# STM32H743 register map
File version: 2.4
CPU: CM7 r0p1, little endian, MPU, FPU, 4 interrupt priority bits
Registers are 32-bit, read-write, reset 0x0 unless marked. A register's access mark holds for its fields unless they carry their own. Offsets are from the block's base; [hi:lo] are bit positions; {n}, {i} and the like mark numbered series; 'fields as' and 'values as' point back to an identical list.

## JPEG — JPEG 编解码器
Base 0x52003000
0x00 CONFR0 wo — JPEG 编解码器控制寄存器
  [0] START — 启动 此位用于启动或停止编码/解码过程。读取此位始终返回 0。
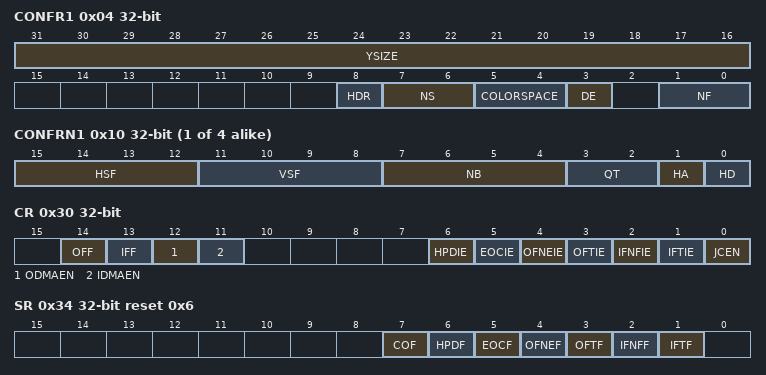
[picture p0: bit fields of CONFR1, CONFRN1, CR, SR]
0x04 CONFR1 — JPEG 编解码器配置寄存器 1
  [31:16] YSIZE — Y 方向尺寸 此字段定义源图像的行数。
  [8] HDR — 头处理 此位使能头处理（生成/解析）。
  [7:6] NS — 扫描分量数 此字段定义扫描头标记段的分量数减 1。
  [5:4] COLORSPACE — 颜色空间 此字段定义输出流中要插入的量化表数量减 1。
  [3] DE — 解码使能 此位选择编码或解码过程。
  [1:0] NF — 颜色分量数 此字段定义颜色分量数减 1。
0x08 CONFR2 — JPEG 编解码器配置寄存器 2
  [25:0] NMCU — MCU 数量 编码时：此字段定义要编码的 MCU 单元数减 1。解码时：此字段指示要解码的完整 MCU 单元数减 1（此字段在 JPEG 头解析后更新）。如果解码图像的 X 或 Y 尺寸不是 8 或 16 的倍数（取决于子采样过程），则需将由此产生的不完整或空的 MCU 计入此值，以得到生成的总 MCU 数。
0x0C CONFR3 — JPEG 编解码器配置寄存器 3
  [31:16] XSIZE — X 方向尺寸 此字段定义每行的像素数。
{0xC+4i} CONFRN{i} (i=1..4) — JPEG 编解码器配置寄存器 4~7
  [15:12] HSF — 水平采样因子 分量 i 的水平采样因子。
  [11:8] VSF — 垂直采样因子 分量 i 的垂直采样因子。
  [7:4] NB — 块数 MCU 中属于特定颜色的数据单元数减 1。
  [3:2] QT — 量化表 选择与颜色分量关联的量化表。
  [1] HA — Huffman AC 选择用于编码 AC 系数的 Huffman 表。
  [0] HD — Huffman DC 选择用于编码 DC 系数的 Huffman 表。
0x30 CR — JPEG 控制寄存器
  [14] OFF — 输出 FIFO 刷新 此位刷新输出 FIFO。读取此位始终返回 0。
  [13] IFF — 输入 FIFO 刷新 此位刷新输入 FIFO。读取此位始终返回 0。
  [12] ODMAEN — 输出 DMA 使能 使能输出 FIFO 的 DMA 请求生成。
  [11] IDMAEN — 输入 DMA 使能 使能输入 FIFO 的 DMA 请求生成。
  [6] HPDIE — 头解析完成中断使能 此位使能头解析操作完成时的中断生成。
  [5] EOCIE — 转换完成中断使能 此位使能转换完成时的中断生成。
  [4] OFNEIE — 输出 FIFO 非空中断使能 此位使能输出 FIFO 非空时的中断生成。
  [3] OFTIE — 输出 FIFO 阈值中断使能 此位使能输出 FIFO 达到阈值时的中断生成。
  [2] IFNFIE — 输入 FIFO 非满中断使能 此位使能输入 FIFO 非满时的中断生成。
  [1] IFTIE — 输入 FIFO 阈值中断使能 此位使能输入 FIFO 达到阈值时的中断生成。
  [0] JCEN — JPEG 内核使能 使能 JPEG 编解码器内核。
0x34 SR ro reset 0x6 — JPEG 状态寄存器
  [7] COF — 编解码器运行标志 当 JPEG 编解码器正在执行操作（编码或解码）时，此位置 1。
  [6] HPDF — 头解析完成标志 在解码模式下，当 JPEG 编解码器完成头解析且内部寄存器已更新时，此位置 1。
  [5] EOCF — 转换完成标志 当 JPEG 编解码器内核完成编码或解码过程且最后一笔数据已发送到输出 FIFO 时，此位置 1。
  [4] OFNEF — 输出 FIFO 非空标志 当输出 FIFO 非空（有数据可用）时，此位置 1。
  [3] OFTF — 输出 FIFO 阈值标志 当输出 FIFO 非空且已达到其阈值时，此位置 1。
  [2] IFNFF — 输入 FIFO 非满标志 当输入 FIFO 未满（可写入数据）时，此位置 1。
  [1] IFTF — 输入 FIFO 阈值标志 当输入 FIFO 未满且低于其阈值时，此位置 1。
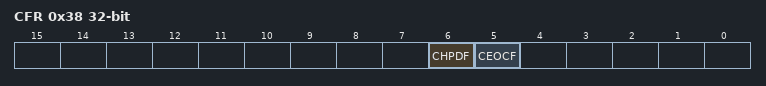
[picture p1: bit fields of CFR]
0x38 CFR — JPEG 标志清零寄存器
  [6] CHPDF — 清除头解析完成标志 写入 1 将清除 JPEG 状态寄存器中的头解析完成标志。
  [5] CEOCF — 清除转换完成标志 写入 1 将清除 JPEG 状态寄存器中的转换完成标志。
0x40 DIR wo — JPEG 数据输入寄存器
  [31:0] DATAIN — 数据输入 输入 FIFO 数据寄存器。
0x44 DOR ro — JPEG 数据输出寄存器
  [31:0] DATAOUT — 数据输出 输出 FIFO 数据寄存器。

## RNG — 随机数发生器
Base 0x48021800
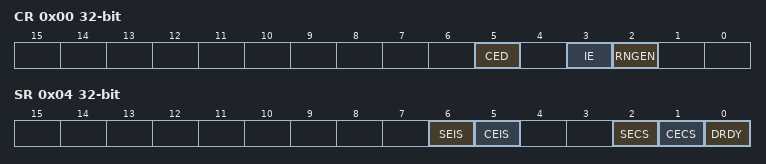
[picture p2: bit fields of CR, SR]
0x00 CR — RNG 控制寄存器
  [5] CED — 时钟错误检测 注意：仅在选择了 ck_rc48 或 ck_pll1_q（ck_pll1_q = 48MHz）时钟源时，时钟错误检测才可使用；否则 CED 位必须置为 1。当 RNG 外设已使能时，不能动态启用或禁用时钟错误检测，如需启用或禁用 CED，必须先禁用 RNG。
  [3] IE — 中断使能
  [2] RNGEN — 随机数发生器使能
0x04 SR access per field — RNG 状态寄存器
  [6] SEIS rw — 种子错误中断状态 此位与 SECS 同时置位，写 0 将其清除。** 连续 64 位以上为相同值（全 0 或全 1）** 连续 32 次以上 0 和 1 交替（0101010101...01）若 RNG_CR 寄存器中 IE = 1，则有中断挂起。
  [5] CEIS rw — 时钟错误中断状态 此位与 CECS 同时置位，写 0 将其清除。若 RNG_CR 寄存器中 IE = 1，则有中断挂起。注意：若 RNG_CR 中的 CED（时钟错误检测）位为 1，此位无意义。
  [2] SECS ro — 种子错误当前状态 ** 连续 64 位以上为相同值（全 0 或全 1）** 连续 32 次以上 0 和 1 交替（0101010101...01）
  [1] CECS ro — 时钟错误当前状态 注意：若 RNG_CR 中的 CED（时钟错误检测）位为 1，此位无意义。
  [0] DRDY ro — 数据就绪 注意：若 RNG_CR 中 IE=1，则当 DRDY=1 时会产生中断。该位在外设禁用时也可能置位。当输出缓冲区变空（读取 RNG_DR 后），此位恢复为 0，直到生成新的随机值。
0x08 DR ro — RNG_DR 寄存器为只读寄存器，读取时返回 32 位随机值。当 DRDY=1 时，该寄存器内容有效，即使 RNGEN=0 也如此。
  [31:0] RNDATA — 随机数据 32 位随机数据，当 DRDY=1 时有效。

## RTC
Base 0x58004000
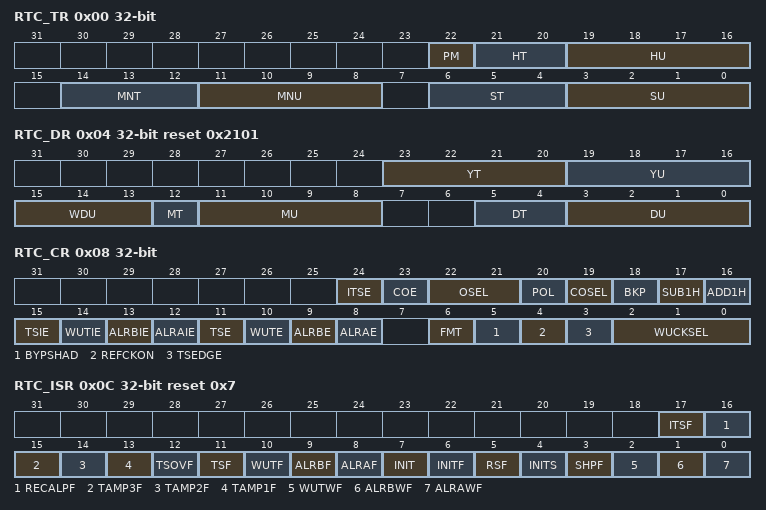
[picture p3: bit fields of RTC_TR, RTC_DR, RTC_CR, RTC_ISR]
0x00 RTC_TR — 日历时间影子寄存器
  [22] PM — AM/PM 指示
  [21:20] HT — 时十位（BCD 格式）
  [19:16] HU — 时个位（BCD 格式）
  [14:12] MNT — 分十位（BCD 格式）
  [11:8] MNU — 分个位（BCD 格式）
  [6:4] ST — 秒十位（BCD 格式）
  [3:0] SU — 秒个位（BCD 格式）
0x04 RTC_DR reset 0x2101 — 日历日期影子寄存器
  [23:20] YT — 年十位（BCD 格式）
  [19:16] YU — 年个位（BCD 格式）
  [15:13] WDU — 星期个位（BCD 格式）
  [12] MT — 月十位（BCD 格式）
  [11:8] MU — 月个位（BCD 格式）
  [5:4] DT — 日十位（BCD 格式）
  [3:0] DU — 日个位（BCD 格式）
0x08 RTC_CR access per field — RTC 控制寄存器
  [24] ITSE rw — 内部时间戳使能
  [23] COE rw — 校准输出使能
  [22:21] OSEL rw — 输出选择
  [20] POL rw — 输出极性
  [19] COSEL rw — 校准输出选择
  [18] BKP rw — 备份寄存器
  [17] SUB1H wo — 减 1 小时
  [16] ADD1H wo — 加 1 小时
  [15] TSIE rw — 时间戳中断使能
  [14] WUTIE rw — 唤醒定时器中断使能
  [13] ALRBIE rw — 闹钟 B 中断使能
  [12] ALRAIE rw — 闹钟 A 中断使能
  [11] TSE rw — 时间戳使能
  [10] WUTE rw — 唤醒定时器使能
  [9] ALRBE rw — 闹钟 B 使能
  [8] ALRAE rw — 闹钟 A 使能
  [6] FMT rw — 小时格式
  [5] BYPSHAD rw — 旁路影子寄存器
  [4] REFCKON rw — 参考时钟检测使能
  [3] TSEDGE rw — 时间戳事件触发沿
  [2:0] WUCKSEL rw — 唤醒时钟选择
0x0C RTC_ISR access per field reset 0x7 — RTC 初始化和状态寄存器
  [17] ITSF rw — 内部时间戳标志
  [16] RECALPF ro — 重新校准挂起标志
  [15] TAMP3F rw — 入侵检测 3 事件标志
  [14] TAMP2F rw — 入侵检测 2 事件标志
  [13] TAMP1F rw — 入侵检测 1 事件标志
  [12] TSOVF rw — 时间戳溢出标志
  [11] TSF rw — 时间戳标志
  [10] WUTF rw — 唤醒定时器标志
  [9] ALRBF rw — 闹钟 B 标志
  [8] ALRAF rw — 闹钟 A 标志
  [7] INIT rw — 初始化模式
  [6] INITF ro — 初始化模式标志
  [5] RSF rw — 寄存器同步标志
  [4] INITS ro — 初始化状态标志
  [3] SHPF ro — 移位操作挂起标志
  [2] WUTWF ro — 唤醒定时器写标志
  [1] ALRBWF ro — 闹钟 B 写标志
  [0] ALRAWF ro — 闹钟 A 写标志
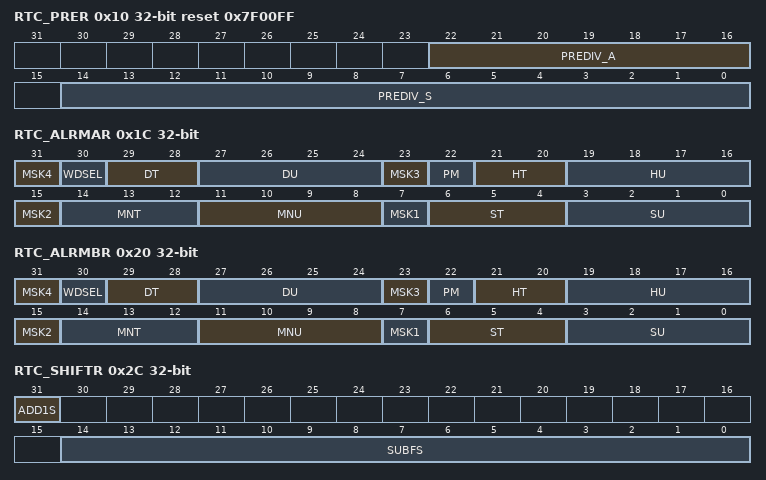
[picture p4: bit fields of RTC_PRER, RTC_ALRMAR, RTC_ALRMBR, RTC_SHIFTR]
0x10 RTC_PRER reset 0x7F00FF — RTC 预分频器寄存器
  [22:16] PREDIV_A — 异步预分频器值
  [14:0] PREDIV_S — 同步预分频器值
0x14 RTC_WUTR reset 0xFFFF — RTC 唤醒定时器寄存器
  [15:0] WUT — 唤醒定时器自动重载值
0x1C RTC_ALRMAR — RTC 闹钟 A 寄存器
  [31] MSK4 — 闹钟日位掩码
  [30] WDSEL — 星期选择
  [29:28] DT — 日十位（BCD 格式）
  [27:24] DU — 日个位（BCD 格式）
  [23] MSK3 — 闹钟时位掩码
  [22] PM — AM/PM 指示
  [21:20] HT — 时十位（BCD 格式）
  [19:16] HU — 时个位（BCD 格式）
  [15] MSK2 — 闹钟分位掩码
  [14:12] MNT — 分十位（BCD 格式）
  [11:8] MNU — 分个位（BCD 格式）
  [7] MSK1 — 闹钟秒位掩码
  [6:4] ST — 秒十位（BCD 格式）
  [3:0] SU — 秒个位（BCD 格式）
0x20 RTC_ALRMBR — RTC 闹钟 B 寄存器
  fields as RTC_ALRMAR
0x24 RTC_WPR wo — RTC 写保护寄存器
  [7:0] KEY — 写保护密钥
0x28 RTC_SSR ro — RTC 亚秒寄存器
  [15:0] SS — 亚秒值
0x2C RTC_SHIFTR wo — RTC 移位控制寄存器
  [31] ADD1S — 加 1 秒
  [14:0] SUBFS — 减亚秒
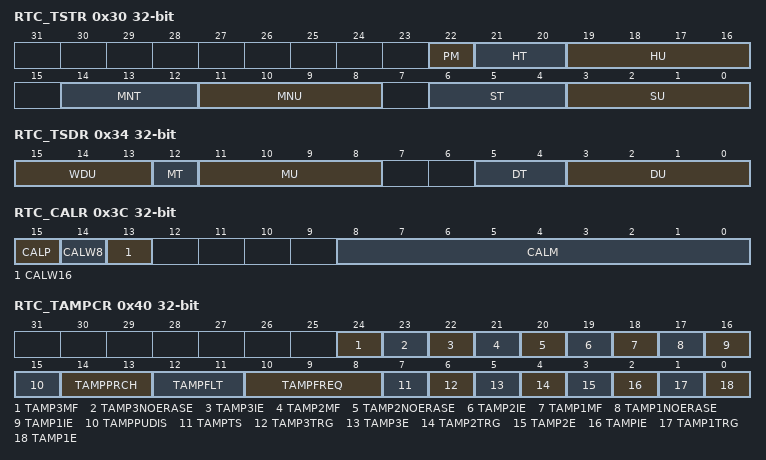
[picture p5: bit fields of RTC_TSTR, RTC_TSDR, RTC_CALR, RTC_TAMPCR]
0x30 RTC_TSTR ro — RTC 时间戳时间寄存器
  fields as RTC_TR
0x34 RTC_TSDR ro — RTC 时间戳日期寄存器
  [15:13] WDU — 星期个位（BCD 格式）
  [12] MT — 月十位（BCD 格式）
  [11:8] MU — 月个位（BCD 格式）
  [5:4] DT — 日十位（BCD 格式）
  [3:0] DU — 日个位（BCD 格式）
0x38 RTC_TSSSR ro — RTC 时间戳亚秒寄存器
  [15:0] SS — 亚秒值
0x3C RTC_CALR — RTC 校准寄存器
  [15] CALP — 校准符号
  [14] CALW8 — 8 秒校准周期选择
  [13] CALW16 — 16 秒校准周期选择
  [8:0] CALM — 校准减量
0x40 RTC_TAMPCR — RTC 入侵检测配置寄存器
  [24] TAMP3MF — 入侵检测 3 屏蔽标志
  [23] TAMP3NOERASE — 入侵检测 3 不擦除
  [22] TAMP3IE — 入侵检测 3 中断使能
  [21] TAMP2MF — 入侵检测 2 屏蔽标志
  [20] TAMP2NOERASE — 入侵检测 2 不擦除
  [19] TAMP2IE — 入侵检测 2 中断使能
  [18] TAMP1MF — 入侵检测 1 屏蔽标志
  [17] TAMP1NOERASE — 入侵检测 1 不擦除
  [16] TAMP1IE — 入侵检测 1 中断使能
  [15] TAMPPUDIS — 入侵检测上拉禁止
  [14:13] TAMPPRCH — 入侵检测预充电
  [12:11] TAMPFLT — 入侵检测滤波器计数
  [10:8] TAMPFREQ — 入侵检测采样频率
  [7] TAMPTS — 入侵检测时激活时间戳
  [6] TAMP3TRG — 入侵检测 3 触发
  [5] TAMP3E — 入侵检测 3 使能
  [4] TAMP2TRG — 入侵检测 2 触发
  [3] TAMP2E — 入侵检测 2 使能
  [2] TAMPIE — 入侵检测中断使能
  [1] TAMP1TRG — 入侵检测 1 触发
  [0] TAMP1E — 入侵检测 1 使能
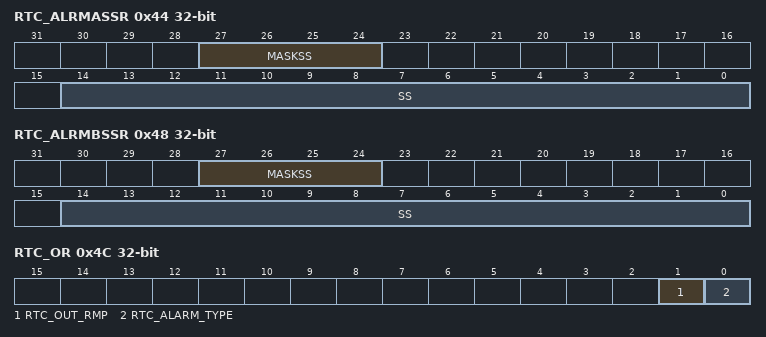
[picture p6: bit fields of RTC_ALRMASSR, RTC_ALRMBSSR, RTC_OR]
0x44 RTC_ALRMASSR — RTC 闹钟 A 亚秒寄存器
  [27:24] MASKSS — 亚秒掩码
  [14:0] SS — 亚秒值
0x48 RTC_ALRMBSSR — RTC 闹钟 B 亚秒寄存器
  [27:24] MASKSS — 亚秒掩码
  [14:0] SS — 亚秒值
0x4C RTC_OR — RTC 选项寄存器
  [1] RTC_OUT_RMP — RTC 输出重映射
  [0] RTC_ALARM_TYPE — RTC 闹钟输出类型
{0x50+4i} RTC_BKP{i}R (i=0..31) — RTC backup registers
  [31:0] BKP — 备份寄存器
